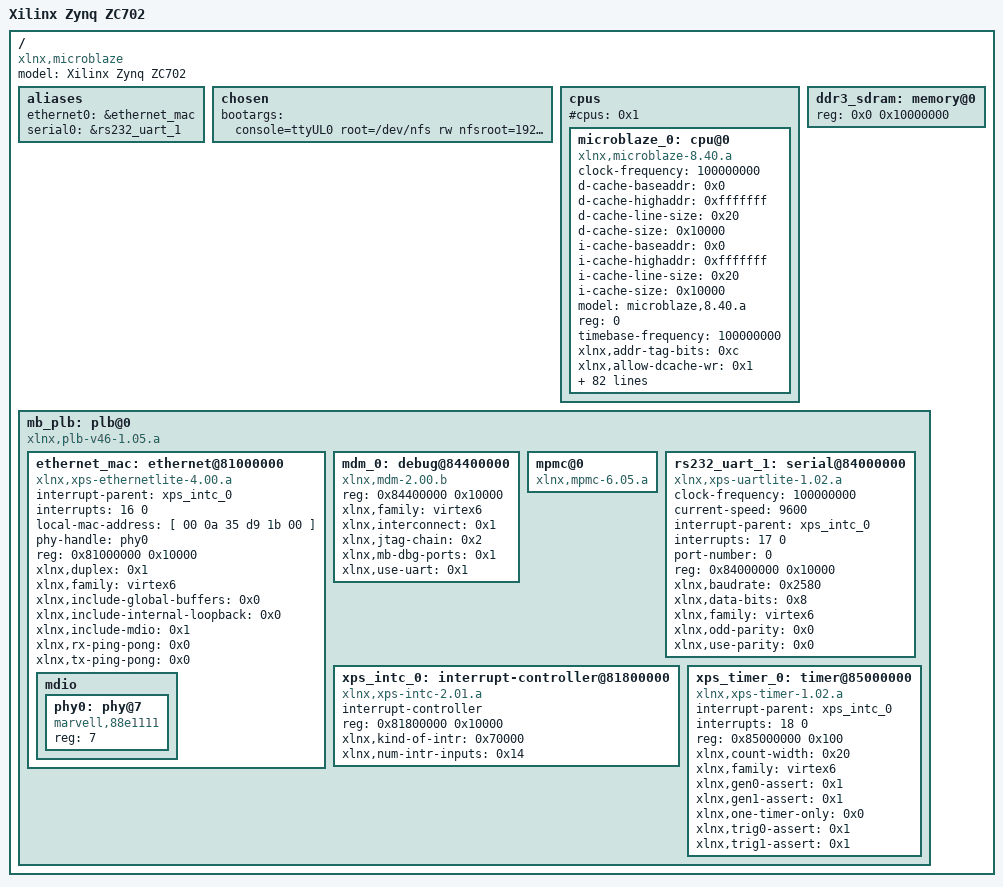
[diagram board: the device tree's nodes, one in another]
/*
 * Device Tree Generator version: 1.3
 *
 * (C) Copyright 2007-2008 Xilinx, Inc.
 * (C) Copyright 2007-2009 Michal Simek
 *
 * Michal SIMEK <monstr@monstr.eu>
 *
 * This program is free software; you can redistribute it and/or
 * modify it under the terms of the GNU General Public License as
 * published by the Free Software Foundation; either version 2 of
 * the License, or (at your option) any later version.
 *
 * This program is distributed in the hope that it will be useful,
 * but WITHOUT ANY WARRANTY; without even the implied warranty of
 * MERCHANTABILITY or FITNESS FOR A PARTICULAR PURPOSE. See the
 * GNU General Public License for more details.
 *
 * You should have received a copy of the GNU General Public License
 * along with this program; if not, write to the Free Software
 * Foundation, Inc., 59 Temple Place, Suite 330, Boston,
 * MA 02111-1307 USA
 *
 * CAUTION: This file is automatically generated by libgen.
 * Version: Xilinx EDK 14.2 EDK_P.28xd
 *
 * XPS project directory: device_tree_generator
 */

/dts-v1/;
/ {
	#address-cells = <1>;
	#size-cells = <1>;
	compatible = "xlnx,microblaze";
	model = "Xilinx Zynq ZC702";
	aliases {
		ethernet0 = &ethernet_mac;
		serial0 = &rs232_uart_1;
	} ;
	chosen {
		bootargs = "console=ttyUL0 root=/dev/nfs rw nfsroot=192.168.31.1:/exports/rootfs_mb,tcp ip=192.168.31.2::192.168.31.1:255.255.255.0:reconos:eth0:off";
	} ;
	cpus {
		#address-cells = <1>;
		#cpus = <0x1>;
		#size-cells = <0>;
		microblaze_0: cpu@0 {
			clock-frequency = <100000000>;
			compatible = "xlnx,microblaze-8.40.a";
			d-cache-baseaddr = <0x0>;
			d-cache-highaddr = <0xfffffff>;
			d-cache-line-size = <0x20>;
			d-cache-size = <0x10000>;
			device_type = "cpu";
			i-cache-baseaddr = <0x0>;
			i-cache-highaddr = <0xfffffff>;
			i-cache-line-size = <0x20>;
			i-cache-size = <0x10000>;
			model = "microblaze,8.40.a";
			reg = <0>;
			timebase-frequency = <100000000>;
			xlnx,addr-tag-bits = <0xc>;
			xlnx,allow-dcache-wr = <0x1>;
			xlnx,allow-icache-wr = <0x1>;
			xlnx,area-optimized = <0x0>;
			xlnx,avoid-primitives = <0x0>;
			xlnx,branch-target-cache-size = <0x1>;
			xlnx,cache-byte-size = <0x10000>;
			xlnx,d-axi = <0x0>;
			xlnx,d-lmb = <0x0>;
			xlnx,d-plb = <0x1>;
			xlnx,data-size = <0x20>;
			xlnx,dcache-addr-tag = <0xc>;
			xlnx,dcache-always-used = <0x1>;
			xlnx,dcache-byte-size = <0x10000>;
			xlnx,dcache-data-width = <0x0>;
			xlnx,dcache-force-tag-lutram = <0x0>;
			xlnx,dcache-interface = <0x1>;
			xlnx,dcache-line-len = <0x8>;
			xlnx,dcache-use-fsl = <0x1>;
			xlnx,dcache-use-writeback = <0x1>;
			xlnx,dcache-victims = <0x0>;
			xlnx,debug-enabled = <0x1>;
			xlnx,div-zero-exception = <0x1>;
			xlnx,dynamic-bus-sizing = <0x1>;
			xlnx,ecc-use-ce-exception = <0x0>;
			xlnx,edge-is-positive = <0x1>;
			xlnx,endianness = <0x0>;
			xlnx,family = "virtex6";
			xlnx,fault-tolerant = <0x0>;
			xlnx,fpu-exception = <0x0>;
			xlnx,freq = <0x5f5e100>;
			xlnx,fsl-data-size = <0x20>;
			xlnx,fsl-exception = <0x0>;
			xlnx,fsl-links = <0x4>;
			xlnx,i-axi = <0x0>;
			xlnx,i-lmb = <0x0>;
			xlnx,i-plb = <0x1>;
			xlnx,icache-always-used = <0x1>;
			xlnx,icache-data-width = <0x0>;
			xlnx,icache-force-tag-lutram = <0x0>;
			xlnx,icache-interface = <0x0>;
			xlnx,icache-line-len = <0x8>;
			xlnx,icache-streams = <0x1>;
			xlnx,icache-use-fsl = <0x1>;
			xlnx,icache-victims = <0x8>;
			xlnx,ill-opcode-exception = <0x1>;
			xlnx,instance = "microblaze_0";
			xlnx,interconnect = <0x1>;
			xlnx,interrupt-is-edge = <0x0>;
			xlnx,lockstep-slave = <0x0>;
			xlnx,mmu-dtlb-size = <0x4>;
			xlnx,mmu-itlb-size = <0x2>;
			xlnx,mmu-privileged-instr = <0x0>;
			xlnx,mmu-tlb-access = <0x3>;
			xlnx,mmu-zones = <0x2>;
			xlnx,number-of-pc-brk = <0x1>;
			xlnx,number-of-rd-addr-brk = <0x0>;
			xlnx,number-of-wr-addr-brk = <0x0>;
			xlnx,opcode-0x0-illegal = <0x1>;
			xlnx,optimization = <0x0>;
			xlnx,pc-width = <0x20>;
			xlnx,pvr = <0x2>;
			xlnx,pvr-user1 = <0x0>;
			xlnx,pvr-user2 = <0x0>;
			xlnx,reset-msr = <0x0>;
			xlnx,sco = <0x0>;
			xlnx,stream-interconnect = <0x0>;
			xlnx,unaligned-exceptions = <0x1>;
			xlnx,use-barrel = <0x1>;
			xlnx,use-branch-target-cache = <0x0>;
			xlnx,use-dcache = <0x1>;
			xlnx,use-div = <0x1>;
			xlnx,use-ext-brk = <0x1>;
			xlnx,use-ext-nm-brk = <0x1>;
			xlnx,use-extended-fsl-instr = <0x0>;
			xlnx,use-fpu = <0x2>;
			xlnx,use-hw-mul = <0x2>;
			xlnx,use-icache = <0x1>;
			xlnx,use-interrupt = <0x1>;
			xlnx,use-mmu = <0x3>;
			xlnx,use-msr-instr = <0x1>;
			xlnx,use-pcmp-instr = <0x1>;
			xlnx,use-reorder-instr = <0x1>;
			xlnx,use-stack-protection = <0x0>;
		} ;
	} ;
	ddr3_sdram: memory@0 {
		device_type = "memory";
		reg = < 0x0 0x10000000 >;
	} ;
	mb_plb: plb@0 {
		#address-cells = <1>;
		#size-cells = <1>;
		compatible = "xlnx,plb-v46-1.05.a", "xlnx,plb-v46-1.00.a", "simple-bus";
		ranges ;
		ethernet_mac: ethernet@81000000 {
			compatible = "xlnx,xps-ethernetlite-4.00.a", "xlnx,xps-ethernetlite-1.00.a";
			device_type = "network";
			interrupt-parent = <&xps_intc_0>;
			interrupts = < 16 0 >;
			local-mac-address = [ 00 0a 35 d9 1b 00 ];
			phy-handle = <&phy0>;
			reg = < 0x81000000 0x10000 >;
			xlnx,duplex = <0x1>;
			xlnx,family = "virtex6";
			xlnx,include-global-buffers = <0x0>;
			xlnx,include-internal-loopback = <0x0>;
			xlnx,include-mdio = <0x1>;
			xlnx,rx-ping-pong = <0x0>;
			xlnx,tx-ping-pong = <0x0>;
			mdio {
				#address-cells = <1>;
				#size-cells = <0>;
				phy0: phy@7 {
					compatible = "marvell,88e1111";
					device_type = "ethernet-phy";
					reg = <7>;
				} ;
			} ;
		} ;
		mdm_0: debug@84400000 {
			compatible = "xlnx,mdm-2.00.b";
			reg = < 0x84400000 0x10000 >;
			xlnx,family = "virtex6";
			xlnx,interconnect = <0x1>;
			xlnx,jtag-chain = <0x2>;
			xlnx,mb-dbg-ports = <0x1>;
			xlnx,use-uart = <0x1>;
		} ;
		mpmc@0 {
			#address-cells = <1>;
			#size-cells = <1>;
			compatible = "xlnx,mpmc-6.05.a";
			ranges ;
		} ;
		rs232_uart_1: serial@84000000 {
			clock-frequency = <100000000>;
			compatible = "xlnx,xps-uartlite-1.02.a", "xlnx,xps-uartlite-1.00.a";
			current-speed = <9600>;
			device_type = "serial";
			interrupt-parent = <&xps_intc_0>;
			interrupts = < 17 0 >;
			port-number = <0>;
			reg = < 0x84000000 0x10000 >;
			xlnx,baudrate = <0x2580>;
			xlnx,data-bits = <0x8>;
			xlnx,family = "virtex6";
			xlnx,odd-parity = <0x0>;
			xlnx,use-parity = <0x0>;
		} ;
		xps_intc_0: interrupt-controller@81800000 {
			#interrupt-cells = <0x2>;
			compatible = "xlnx,xps-intc-2.01.a", "xlnx,xps-intc-1.00.a";
			interrupt-controller ;
			reg = < 0x81800000 0x10000 >;
			xlnx,kind-of-intr = <0x70000>;
			xlnx,num-intr-inputs = <0x14>;
		} ;
		xps_timer_0: timer@85000000 {
			compatible = "xlnx,xps-timer-1.02.a", "xlnx,xps-timer-1.00.a";
			interrupt-parent = <&xps_intc_0>;
			interrupts = < 18 0 >;
			reg = < 0x85000000 0x100 >;
			xlnx,count-width = <0x20>;
			xlnx,family = "virtex6";
			xlnx,gen0-assert = <0x1>;
			xlnx,gen1-assert = <0x1>;
			xlnx,one-timer-only = <0x0>;
			xlnx,trig0-assert = <0x1>;
			xlnx,trig1-assert = <0x1>;
		} ;
	} ;
} ;
